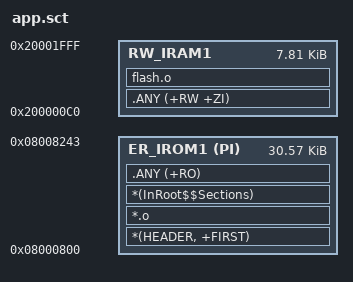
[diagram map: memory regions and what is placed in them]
; *************************************************************
; *** Scatter-Loading Description File generated by uVision ***
; *************************************************************

LR_IROM1 0x08000800 0x00007C00  {    ; load region size_region
  ER_IROM1 0x08000800 PI 0x00007A44 {  ; load address = execution address
   *(HEADER, +FIRST)
   *.o
   *(InRoot$$Sections)
   .ANY (+RO)
  }
   
  RW_IRAM1 0x200000C0 0x00001F40  {  ; RW data
   .ANY (+RW +ZI)
   flash.o
  }
}

